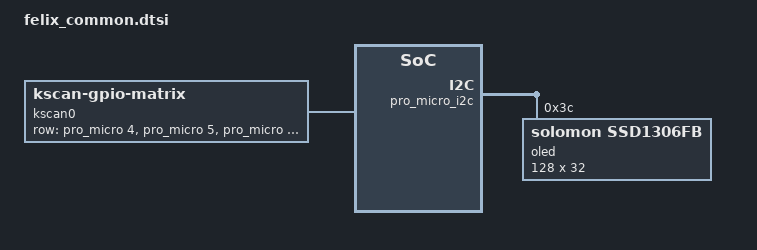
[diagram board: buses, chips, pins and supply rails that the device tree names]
/*
 * Copyright (c) 2020 The ZMK Contributors
 *
 * SPDX-License-Identifier: MIT
 */

/*
 * Hardware shared by every build of a Felix PCB: the split Felix halves
 * (felix_left/felix_right) and the standalone Halfix shields (halfix/halfix_mirrored).
 * Column GPIOs are per side: see felix_left_cols.dtsi and felix_right_cols.dtsi.
 */

/ {
    chosen {
        zephyr,display = &oled;
    };

    kscan0: kscan {
        compatible = "zmk,kscan-gpio-matrix";
        wakeup-source;

        diode-direction = "col2row";
        row-gpios
            = <&pro_micro 4 (GPIO_ACTIVE_HIGH | GPIO_PULL_DOWN)>
            , <&pro_micro 5 (GPIO_ACTIVE_HIGH | GPIO_PULL_DOWN)>
            , <&pro_micro 6 (GPIO_ACTIVE_HIGH | GPIO_PULL_DOWN)>
            , <&pro_micro 7 (GPIO_ACTIVE_HIGH | GPIO_PULL_DOWN)>
            , <&pro_micro 8 (GPIO_ACTIVE_HIGH | GPIO_PULL_DOWN)>
            ;
    };
};

&pro_micro_i2c {
    status = "okay";

    oled: ssd1306@3c {
        compatible = "solomon,ssd1306fb";
        reg = <0x3c>;
        width = <128>;
        height = <32>;
        segment-offset = <0>;
        page-offset = <0>;
        display-offset = <0>;
        multiplex-ratio = <31>;
        segment-remap;
        com-invdir;
        com-sequential;
        inversion-on;
        prechargep = <0x22>;
    };
};
